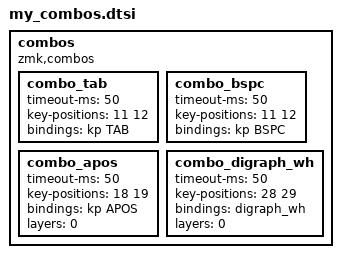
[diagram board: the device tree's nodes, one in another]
/*
        Key Positions for A.dux

0   1   2   3   4       5   6   7   8   9
10  11  12  13  14      15  16  17  18  19
20  21  22  23  24      25  26  27  28  29
            30  31      32  33

*/

combos {
    compatible = "zmk,combos";

    combo_tab {
        timeout-ms = <50>;
        key-positions = <11 12>;
        bindings = <&kp TAB>;
    };
    
    combo_bspc {
        timeout-ms = <50>;
        key-positions = <11 12>;
        bindings = <&kp BSPC>;
    };
    
    combo_apos {
        timeout-ms = <50>;
        key-positions = <18 19>;
        bindings = <&kp APOS>;
        layers = <0>;
    };

    combo_digraph_wh {
        timeout-ms = <50>;
        key-positions = <28 29>;
        bindings = <&digraph_wh>;
        layers = <0>;
    };
    
};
